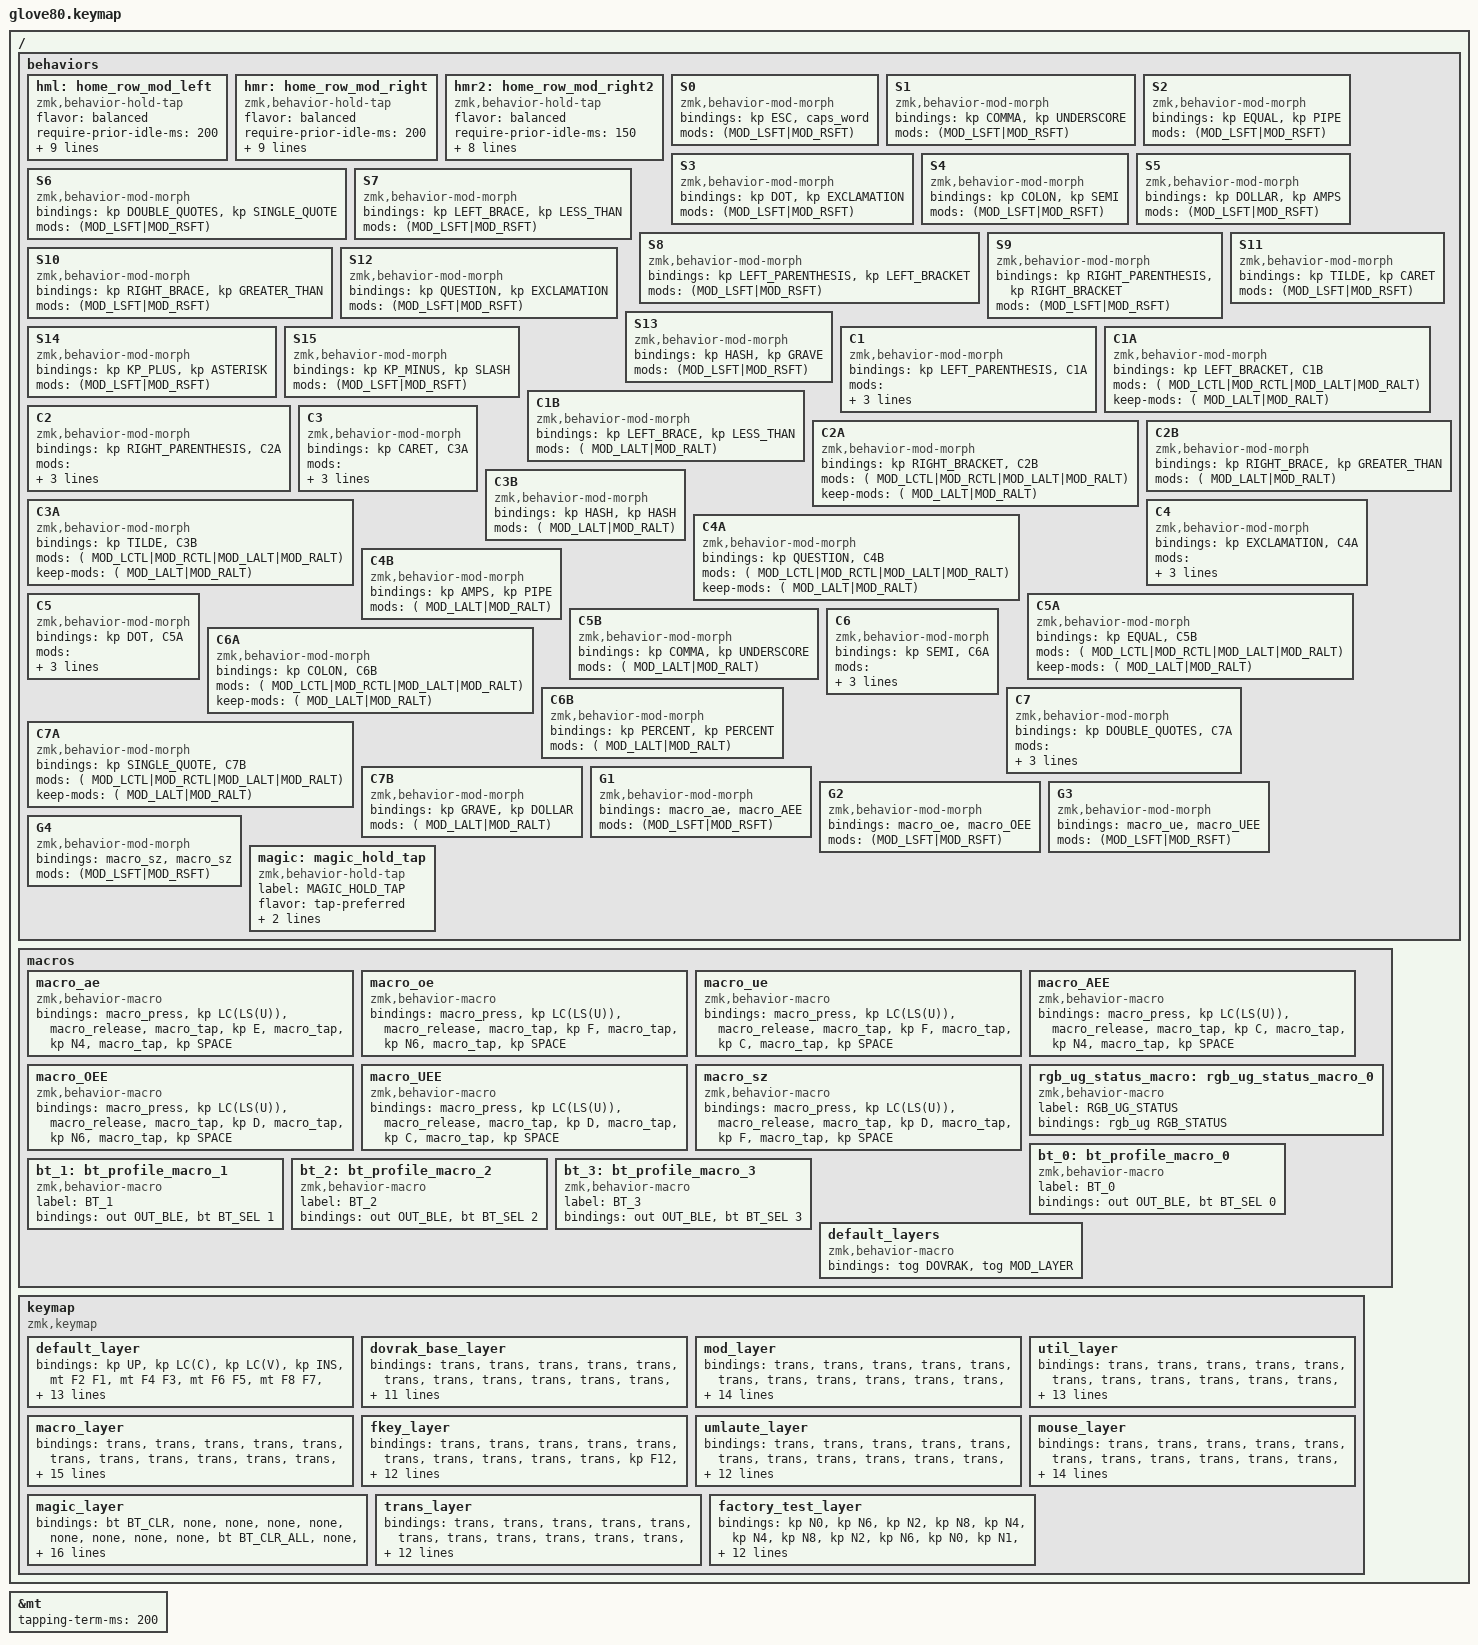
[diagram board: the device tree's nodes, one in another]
/*
 * Copyright (c) 2020 The ZMK Contributors
 *
 * SPDX-License-Identifier: MIT
 */

#include <behaviors.dtsi>
#include <dt-bindings/zmk/keys.h>
#include <dt-bindings/zmk/bt.h>
#include <dt-bindings/zmk/ext_power.h>
#include <dt-bindings/zmk/outputs.h>
#include <dt-bindings/zmk/rgb.h>
#include <dt-bindings/zmk/pointing.h>

#define HYPER LC(LA(LSHFT))

#define CUT   &kp LC(X)
#define COPY  &kp LC(C)
#define PASTE &kp LC(V)
#define PASTE_INS &kp LS(INS)

#define D16 &kp KP_SLASH                          // / when tapped
#define D17 &kp BACKSLASH                         // \ when tapped

// layers
#define DEFAULT                0
#define DOVRAK                 1
#define MOD_LAYER              2
#define UTIL                   3
#define MACRO_LAYER            4
#define FKEYS                  5
#define UMLAUTE                6
#define MOUSE                  7
#define MAGIC                  8

&mt {
//    flavor = "tap-preferred";
    tapping-term-ms = <200>;
};
//        #################################################  CUSTOM KEYS ################################################# //
//        ~~~~~~~~~~~~~~~~~~~~~~~~~~~~~~~~~~~~~~~~~~~~~~~~~  CUSTOM KEYS ~~~~~~~~~~~~~~~~~~~~~~~~~~~~~~~~~~~~~~~~~~~~~~~~~ //

// 0
// 1
// 2
// 3
// 4
// 5
// 6
// 7
// 8
// 9

// bindings = <
// &0     &1     &2     &3     &4                                                             &5     &6     &7     &8     &9
// &10    &11    &12    &13    &14    &15                                              &16    &17    &18    &19    &20    &21
// &22    &23    &24    &25    &26    &27                                              &28    &29    &30    &31    &32    &33
// &34    &35    &36    &37    &38    &39                                              &40    &41    &42    &43    &44    &45
// &46    &47    &48    &49    &50    &51    &52    &53    &54    &55    &56    &57    &58    &59    &60    &61    &62    &63
// &64    &65    &66    &67    &68           &69    &70    &71    &72    &73    &74           &75    &76    &77    &78    &79
// >;



/ {
    behaviors {
//        #################################################  HOMEROW MODS #################################################  //
        hml: home_row_mod_left {
            compatible = "zmk,behavior-hold-tap";
            #binding-cells = <2>;
            flavor = "balanced";
            require-prior-idle-ms = <200>;
            tapping-term-ms = <250>;
            quick-tap-ms = <180>;
            bindings = <&kp>, <&kp>;
            hold-trigger-key-positions = <5>,<6>,<7>,<8>,<9>,<16>,<17>,<18>,<19>,<20>,<21>,<28>,<29>,<30>,<31>,<32>,<33>,<40>,<41>,<42>,<43>,<44>,<45>,<59>,<60>,<61>,<62>,<63>,<75>,<76>,<77>,<78>,<79>, // List of keys on the right side of the keyboard
            <52>,<53>,<54>,<55>,<56>,<57>,<69>,<70>,<71>,<72>,<73>,<74>; //thumbs
            hold-trigger-on-release;
        };
        hmr: home_row_mod_right {
            compatible = "zmk,behavior-hold-tap";
            #binding-cells = <2>;
            flavor = "balanced";
            require-prior-idle-ms = <200>;
            tapping-term-ms = <250>;
            quick-tap-ms = <180>;
            bindings = <&kp>, <&kp>;
            hold-trigger-key-positions = <0>,<1>,<2>,<3>,<4>,<10>,<11>,<12>,<13>,<14>,<15>,<22>,<23>,<24>,<25>,<26>,<27>,<34>,<35>,<36>,<37>,<38>,<39>,<46>,<47>,<48>,<49>,<50>,<51>,<64>,<65>,<66>,<67>,<68>,// List of keys on the left side of the keyboard
            <52>,<53>,<54>,<55>,<56>,<57>,<69>,<70>,<71>,<72>,<73>,<74>; //thumbs
            hold-trigger-on-release;
        };

       hmr2: home_row_mod_right2 {
           compatible = "zmk,behavior-hold-tap";
           #binding-cells = <2>;
           flavor = "balanced";
           require-prior-idle-ms = <150>;
           tapping-term-ms = <180>;
           quick-tap-ms = <125>;
           bindings = <&mo>, <&kp>;
           hold-trigger-key-positions = <0>,<1>,<2>,<3>,<4>,<10>,<11>,<12>,<13>,<14>,<15>,<22>,<23>,<24>,<25>,<26>,<27>,<34>,<35>,<36>,<37>,<38>,<39>,<46>,<47>,<48>,<49>,<50>,<51>,<64>,<65>,<66>,<67>,<68>;// List of keys on the left side of the keyboard
           hold-trigger-on-release;
       };
//        ~~~~~~~~~~~~~~~~~~~~~~~~~~~~~~~~~~~~~~~~~~~~~~~~  HOMEROW MODS ~~~~~~~~~~~~~~~~~~~~~~~~~~~~~~~~~~~~~~~~~~~~~~~~  //
//        #################################################  CUSTOM KEYS ################################################# //
        S0: S0 {
                    compatible = "zmk,behavior-mod-morph";
                    #binding-cells = <0>;
                    bindings = <&kp ESC>, <&caps_word>;
                    mods = <(MOD_LSFT|MOD_RSFT)>;
        };

        S1: S1   { compatible = "zmk,behavior-mod-morph"; #binding-cells = <0>; bindings = <&kp COMMA>             , <&kp UNDERSCORE>      ; mods = <(MOD_LSFT|MOD_RSFT)>; };
        S2: S2   { compatible = "zmk,behavior-mod-morph"; #binding-cells = <0>; bindings = <&kp EQUAL>             , <&kp PIPE>            ; mods = <(MOD_LSFT|MOD_RSFT)>; };
        S3: S3   { compatible = "zmk,behavior-mod-morph"; #binding-cells = <0>; bindings = <&kp DOT>               , <&kp EXCLAMATION>     ; mods = <(MOD_LSFT|MOD_RSFT)>; };
        S4: S4   { compatible = "zmk,behavior-mod-morph"; #binding-cells = <0>; bindings = <&kp COLON>             , <&kp SEMI>            ; mods = <(MOD_LSFT|MOD_RSFT)>; };
        S5: S5   { compatible = "zmk,behavior-mod-morph"; #binding-cells = <0>; bindings = <&kp DOLLAR>            , <&kp AMPS>            ; mods = <(MOD_LSFT|MOD_RSFT)>; };
        S6: S6   { compatible = "zmk,behavior-mod-morph"; #binding-cells = <0>; bindings = <&kp DOUBLE_QUOTES>     , <&kp SINGLE_QUOTE>    ; mods = <(MOD_LSFT|MOD_RSFT)>; };
        S7: S7   { compatible = "zmk,behavior-mod-morph"; #binding-cells = <0>; bindings = <&kp LEFT_BRACE>        , <&kp LESS_THAN>       ; mods = <(MOD_LSFT|MOD_RSFT)>; };
        S8: S8   { compatible = "zmk,behavior-mod-morph"; #binding-cells = <0>; bindings = <&kp LEFT_PARENTHESIS>  , <&kp LEFT_BRACKET>    ; mods = <(MOD_LSFT|MOD_RSFT)>; };
        S9: S9   { compatible = "zmk,behavior-mod-morph"; #binding-cells = <0>; bindings = <&kp RIGHT_PARENTHESIS> , <&kp RIGHT_BRACKET>   ; mods = <(MOD_LSFT|MOD_RSFT)>; };
        S10: S10 { compatible = "zmk,behavior-mod-morph"; #binding-cells = <0>; bindings = <&kp RIGHT_BRACE>       , <&kp GREATER_THAN>    ; mods = <(MOD_LSFT|MOD_RSFT)>; };
        S11: S11 { compatible = "zmk,behavior-mod-morph"; #binding-cells = <0>; bindings = <&kp TILDE>             , <&kp CARET>           ; mods = <(MOD_LSFT|MOD_RSFT)>; };
        S12: S12 { compatible = "zmk,behavior-mod-morph"; #binding-cells = <0>; bindings = <&kp QUESTION>          , <&kp EXCLAMATION>     ; mods = <(MOD_LSFT|MOD_RSFT)>; };
        S13: S13 { compatible = "zmk,behavior-mod-morph"; #binding-cells = <0>; bindings = <&kp HASH>              , <&kp GRAVE>           ; mods = <(MOD_LSFT|MOD_RSFT)>; };
        S14: S14 { compatible = "zmk,behavior-mod-morph"; #binding-cells = <0>; bindings = <&kp KP_PLUS>           , <&kp ASTERISK>        ; mods = <(MOD_LSFT|MOD_RSFT)>; };
        S15: S15 { compatible = "zmk,behavior-mod-morph"; #binding-cells = <0>; bindings = <&kp KP_MINUS>          , <&kp SLASH>           ; mods = <(MOD_LSFT|MOD_RSFT)>; };

        // S7 & S8 ([{<
        C1:  C1    { compatible = "zmk,behavior-mod-morph"; #binding-cells = <0>; bindings = <&kp LEFT_PARENTHESIS>   , <&C1A>              ; mods = <(MOD_LSFT|MOD_RSFT|MOD_LCTL|MOD_RCTL|MOD_LALT|MOD_RALT)>; keep-mods = <(MOD_LCTL|MOD_RCTL|MOD_LALT|MOD_RALT)>; };
        C1A: C1A   { compatible = "zmk,behavior-mod-morph"; #binding-cells = <0>; bindings = <&kp LEFT_BRACKET>       , <&C1B>              ; mods = <(                  MOD_LCTL|MOD_RCTL|MOD_LALT|MOD_RALT)>; keep-mods = <(                  MOD_LALT|MOD_RALT)>; };
        C1B: C1B   { compatible = "zmk,behavior-mod-morph"; #binding-cells = <0>; bindings = <&kp LEFT_BRACE>         , <&kp LESS_THAN>     ; mods = <(                                    MOD_LALT|MOD_RALT)>;                                                      };
        // S9 & S10 )]}>
        C2:  C2    { compatible = "zmk,behavior-mod-morph"; #binding-cells = <0>; bindings = <&kp RIGHT_PARENTHESIS>  , <&C2A>             ; mods = <(MOD_LSFT|MOD_RSFT|MOD_LCTL|MOD_RCTL|MOD_LALT|MOD_RALT)>; keep-mods = <(MOD_LCTL|MOD_RCTL|MOD_LALT|MOD_RALT)>; };
        C2A: C2A   { compatible = "zmk,behavior-mod-morph"; #binding-cells = <0>; bindings = <&kp RIGHT_BRACKET>      , <&C2B>             ; mods = <(                  MOD_LCTL|MOD_RCTL|MOD_LALT|MOD_RALT)>; keep-mods = <(                  MOD_LALT|MOD_RALT)>; };
        C2B: C2B   { compatible = "zmk,behavior-mod-morph"; #binding-cells = <0>; bindings = <&kp RIGHT_BRACE>        , <&kp GREATER_THAN> ; mods = <(                                    MOD_LALT|MOD_RALT)>;                                                      };

        // ^~#
        C3:  C3    { compatible = "zmk,behavior-mod-morph"; #binding-cells = <0>; bindings = <&kp CARET>              , <&C3A>             ; mods = <(MOD_LSFT|MOD_RSFT|MOD_LCTL|MOD_RCTL|MOD_LALT|MOD_RALT)>; keep-mods = <(MOD_LCTL|MOD_RCTL|MOD_LALT|MOD_RALT)>; };
        C3A: C3A   { compatible = "zmk,behavior-mod-morph"; #binding-cells = <0>; bindings = <&kp TILDE>              , <&C3B>             ; mods = <(                  MOD_LCTL|MOD_RCTL|MOD_LALT|MOD_RALT)>; keep-mods = <(                  MOD_LALT|MOD_RALT)>; };
        C3B: C3B   { compatible = "zmk,behavior-mod-morph"; #binding-cells = <0>; bindings = <&kp HASH>               , <&kp HASH>         ; mods = <(                                    MOD_LALT|MOD_RALT)>;                                                      };

        // !?&|
        C4:  C4    { compatible = "zmk,behavior-mod-morph"; #binding-cells = <0>; bindings = <&kp EXCLAMATION>        , <&C4A>             ; mods = <(MOD_LSFT|MOD_RSFT|MOD_LCTL|MOD_RCTL|MOD_LALT|MOD_RALT)>; keep-mods = <(MOD_LCTL|MOD_RCTL|MOD_LALT|MOD_RALT)>; };
        C4A: C4A   { compatible = "zmk,behavior-mod-morph"; #binding-cells = <0>; bindings = <&kp QUESTION>           , <&C4B>             ; mods = <(                  MOD_LCTL|MOD_RCTL|MOD_LALT|MOD_RALT)>; keep-mods = <(                  MOD_LALT|MOD_RALT)>; };
        C4B: C4B   { compatible = "zmk,behavior-mod-morph"; #binding-cells = <0>; bindings = <&kp AMPS>               , <&kp PIPE>         ; mods = <(                                    MOD_LALT|MOD_RALT)>;                                                      };

        // .=,_
        C5:  C5    { compatible = "zmk,behavior-mod-morph"; #binding-cells = <0>; bindings = <&kp DOT>                , <&C5A>             ; mods = <(MOD_LSFT|MOD_RSFT|MOD_LCTL|MOD_RCTL|MOD_LALT|MOD_RALT)>; keep-mods = <(MOD_LCTL|MOD_RCTL|MOD_LALT|MOD_RALT)>; };
        C5A: C5A   { compatible = "zmk,behavior-mod-morph"; #binding-cells = <0>; bindings = <&kp EQUAL>              , <&C5B>             ; mods = <(                  MOD_LCTL|MOD_RCTL|MOD_LALT|MOD_RALT)>; keep-mods = <(                  MOD_LALT|MOD_RALT)>; };
        C5B: C5B   { compatible = "zmk,behavior-mod-morph"; #binding-cells = <0>; bindings = <&kp COMMA>              , <&kp UNDERSCORE>   ; mods = <(                                    MOD_LALT|MOD_RALT)>;                                                      };

        // :;%%
        C6:  C6    { compatible = "zmk,behavior-mod-morph"; #binding-cells = <0>; bindings = <&kp SEMI>               , <&C6A>             ; mods = <(MOD_LSFT|MOD_RSFT|MOD_LCTL|MOD_RCTL|MOD_LALT|MOD_RALT)>; keep-mods = <(MOD_LCTL|MOD_RCTL|MOD_LALT|MOD_RALT)>; };
        C6A: C6A   { compatible = "zmk,behavior-mod-morph"; #binding-cells = <0>; bindings = <&kp COLON>              , <&C6B>             ; mods = <(                  MOD_LCTL|MOD_RCTL|MOD_LALT|MOD_RALT)>; keep-mods = <(                  MOD_LALT|MOD_RALT)>; };
        C6B: C6B   { compatible = "zmk,behavior-mod-morph"; #binding-cells = <0>; bindings = <&kp PERCENT>            , <&kp PERCENT>      ; mods = <(                                    MOD_LALT|MOD_RALT)>;                                                      };

        // "'`
        C7:  C7    { compatible = "zmk,behavior-mod-morph"; #binding-cells = <0>; bindings = <&kp DOUBLE_QUOTES>      , <&C7A>             ; mods = <(MOD_LSFT|MOD_RSFT|MOD_LCTL|MOD_RCTL|MOD_LALT|MOD_RALT)>; keep-mods = <(MOD_LCTL|MOD_RCTL|MOD_LALT|MOD_RALT)>; };
        C7A: C7A   { compatible = "zmk,behavior-mod-morph"; #binding-cells = <0>; bindings = <&kp SINGLE_QUOTE>       , <&C7B>             ; mods = <(                  MOD_LCTL|MOD_RCTL|MOD_LALT|MOD_RALT)>; keep-mods = <(                  MOD_LALT|MOD_RALT)>; };
        C7B: C7B   { compatible = "zmk,behavior-mod-morph"; #binding-cells = <0>; bindings = <&kp GRAVE>              , <&kp DOLLAR>       ; mods = <(                                    MOD_LALT|MOD_RALT)>;                                                      };

        // a A
        G1:  G1    { compatible = "zmk,behavior-mod-morph"; #binding-cells = <0>; bindings = <&macro_ae>   , <&macro_AEE>   ; mods = <(MOD_LSFT|MOD_RSFT)>; };
        G2:  G2    { compatible = "zmk,behavior-mod-morph"; #binding-cells = <0>; bindings = <&macro_oe>   , <&macro_OEE>   ; mods = <(MOD_LSFT|MOD_RSFT)>; };
        G3:  G3    { compatible = "zmk,behavior-mod-morph"; #binding-cells = <0>; bindings = <&macro_ue>   , <&macro_UEE>   ; mods = <(MOD_LSFT|MOD_RSFT)>; };
        G4:  G4    { compatible = "zmk,behavior-mod-morph"; #binding-cells = <0>; bindings = <&macro_sz>   , <&macro_sz>    ; mods = <(MOD_LSFT|MOD_RSFT)>; };
//        ~~~~~~~~~~~~~~~~~~~~~~~~~~~~~~~~~~~~~~~~~~~~~~~~~  CUSTOM KEYS ~~~~~~~~~~~~~~~~~~~~~~~~~~~~~~~~~~~~~~~~~~~~~~~~~ //

        magic: magic_hold_tap {
            compatible = "zmk,behavior-hold-tap";
            label = "MAGIC_HOLD_TAP";
            #binding-cells = <2>;
            flavor = "tap-preferred";
            tapping-term-ms = <200>;
            bindings = <&mo>, <&rgb_ug_status_macro>;
        };
    };

    macros {
//        #################################################  ASCII KEYS ################################################# //
        // ä (U+00E4)
        macro_ae: macro_ae {
            compatible = "zmk,behavior-macro";
            #binding-cells = <0>;
            bindings
              = <&macro_press &kp LC(LS(U))>
              , <&macro_release>
              , <&macro_tap &kp E>
              , <&macro_tap &kp N4>
              , <&macro_tap &kp SPACE>
              ;
        };

        // ö (U+00F6)
        macro_oe: macro_oe {
            compatible = "zmk,behavior-macro";
            #binding-cells = <0>;
            bindings
              = <&macro_press &kp LC(LS(U))>
              , <&macro_release>
              , <&macro_tap &kp F>
              , <&macro_tap &kp N6>
              , <&macro_tap &kp SPACE>
              ;
        };

        // ü (U+00FC)
        macro_ue: macro_ue {
            compatible = "zmk,behavior-macro";
            #binding-cells = <0>;
            bindings
              = <&macro_press &kp LC(LS(U))>
              , <&macro_release>
              , <&macro_tap &kp F>
              , <&macro_tap &kp C>
              , <&macro_tap &kp SPACE>
              ;
        };

        // Ä (U+00C4)
        macro_AEE: macro_AEE {
            compatible = "zmk,behavior-macro";
            #binding-cells = <0>;
            bindings
              = <&macro_press &kp LC(LS(U))>
              , <&macro_release>
              , <&macro_tap &kp C>
              , <&macro_tap &kp N4>
              , <&macro_tap &kp SPACE>
              ;
        };

        // Ö (U+00D6)
        macro_OEE: macro_OEE {
            compatible = "zmk,behavior-macro";
            #binding-cells = <0>;
            bindings
              = <&macro_press &kp LC(LS(U))>
              , <&macro_release>
              , <&macro_tap &kp D>
              , <&macro_tap &kp N6>
              , <&macro_tap &kp SPACE>
              ;
        };

        // Ü (U+00DC)
        macro_UEE: macro_UEE {
            compatible = "zmk,behavior-macro";
            #binding-cells = <0>;
            bindings
              = <&macro_press &kp LC(LS(U))>
              , <&macro_release>
              , <&macro_tap &kp D>
              , <&macro_tap &kp C>
              , <&macro_tap &kp SPACE>
              ;
        };

        // ß (U+00DF)
        macro_sz: macro_sz {
            compatible = "zmk,behavior-macro";
            #binding-cells = <0>;
            bindings
              = <&macro_press &kp LC(LS(U))>
              , <&macro_release>
              , <&macro_tap &kp D>
              , <&macro_tap &kp F>
              , <&macro_tap &kp SPACE>
              ;
        };
//        ~~~~~~~~~~~~~~~~~~~~~~~~~~~~~~~~~~~~~~~~~~~~~~~~~  ASCII KEYS ~~~~~~~~~~~~~~~~~~~~~~~~~~~~~~~~~~~~~~~~~~~~~~~~~ //
        rgb_ug_status_macro: rgb_ug_status_macro_0 {
            label = "RGB_UG_STATUS";
            compatible = "zmk,behavior-macro";
            #binding-cells = <0>;
            bindings
                = <&rgb_ug RGB_STATUS>;
        };

        bt_0: bt_profile_macro_0 {
            label = "BT_0";
            compatible = "zmk,behavior-macro";
            #binding-cells = <0>;
            bindings
                = <&out OUT_BLE>,
                  <&bt BT_SEL 0>;
        };

        bt_1: bt_profile_macro_1 {
            label = "BT_1";
            compatible = "zmk,behavior-macro";
            #binding-cells = <0>;
            bindings
                = <&out OUT_BLE>,
                  <&bt BT_SEL 1>;
        };

        bt_2: bt_profile_macro_2 {
            label = "BT_2";
            compatible = "zmk,behavior-macro";
            #binding-cells = <0>;
            bindings
                = <&out OUT_BLE>,
                  <&bt BT_SEL 2>;
        };

        bt_3: bt_profile_macro_3 {
            label = "BT_3";
            compatible = "zmk,behavior-macro";
            #binding-cells = <0>;
            bindings
                = <&out OUT_BLE>,
                  <&bt BT_SEL 3>;
        };

         default_layers: default_layers {
                      compatible = "zmk,behavior-macro";
                      #binding-cells = <0>;
                      bindings
                        = <&tog DOVRAK>
                        , <&tog MOD_LAYER>
                        ;
                  };
    };

    keymap {
        compatible = "zmk,keymap";

        default_layer {
            // ----------------------------------------------------------------------------------------------------------------------------------------------
            // |            |     |     |      | F1 F2 |                                                         | F3 F4 | F5 F6 | F7 F8 | F9 F10 | F11 F12 |
            // |            |  1  |  2  |  3   | 4     | 5 |                                                 | 6 | 7     | 8     | 9     | 0      |         |
            // |  ESC       |     |     |      |       |   |                                                 |   |       |       |       |        |         |
            // |  TAB CAPS  |     |     |      |       |   |                                                 |   |       |       |       |        |         |
            // |            |     |     |      |       |   | LSHFT | LCTRL | LOWER | | LGUI  | RCTRL | RSHFT |   |       |       |       |        | PGUP    |
            // | MAGIC      | HOME| END | LEFT | RIGHT |   | BSPC  | DEL   | LALT  | | RALT  | RET   | SPACE |   | UP    | DOWN  |       |        | PGDN    |

            bindings = <
            &kp UP         &kp LC(C)       &kp LC(V)    &kp INS     &mt F2 F1                                                                                         &mt F4 F3  &mt F6 F5      &mt F8 F7      &mt F10 F9     &mt F12 F11
            &kp DOWN       &kp N1          &kp N2       &kp N3      &kp N4      &kp N5                                                                        &kp N6  &kp N7     &kp N8         &kp N9         &kp N0         &none
            &kp ESC        &none           &none        &none       &none       &none                                                                         &none   &none      &none          &none          &none          &none
            &kp TAB        &none           &none        &none       &none       &none                                                                         &none   &none      &none          &none          &none          &none
            &none          &none           &none        &none       &none       &none   &kp LSHFT   &kp LCTRL   &kp LGUI   &kp LGUI   &kp RSHFT   &kp DEL     &none   &none      &none          &none          &none          &kp PG_UP
            &magic MAGIC 0 &kp HOME        &kp END      &kp LEFT    &kp RIGHT           &kp SPACE   &kp RET     &kp LALT   &mo MOUSE  &tog MOUSE  &kp BSPC            &kp UP     &kp DOWN       &none          &none          &kp PG_DN
            >;
        };
//        &kp LSHFT   &kp LCTRL   &kp LGUI   &kp LGUI  &kp RCTRL &kp RSHFT
//        &kp BSPC    &kp DEL     &kp LALT   &kp LALT  &kp RET   &kp SPACE

        dovrak_base_layer {

           bindings = <
           &trans      &trans      &trans      &trans      &trans                                                                             &trans      &trans      &trans      &trans      &trans
           &trans      &trans      &trans      &trans      &trans             &trans                                                  &trans  &trans      &trans      &trans      &trans      &trans
           &trans      &C3         &C4         &C5         &C6                &C7                                                     &kp G   &kp K       &kp R       &kp F       &kp J       &mo FKEYS
           &trans      &kp A       &kp O       &kp E       &kp U              &kp I                                                   &kp D   &kp H       &kp T       &kp N       &kp B       &kp X
           &kp V       &kp Z       &kp P       &kp Y       &mo MACRO_LAYER    &kp M   &trans  &trans  &trans  &trans  &trans  &trans  &kp W   &kp S       &kp C       &kp L       &kp Q       &trans
           &trans      &trans      &trans      &trans      &trans                     &trans  &trans  &trans  &trans  &trans  &trans          &trans      &trans      &S14        &S15        &trans
          >;
        };

        mod_layer {

           bindings = <
           &trans  &trans      &trans        &trans         &trans                                                                            &trans         &trans         &trans       &trans           &trans
           &trans  &trans      &trans        &trans         &trans         &trans                                                     &trans  &trans         &trans         &trans       &trans           &trans
           &trans  &trans      &trans        &trans         &trans         &trans                                                     &trans  &trans         &trans         &trans       &trans           &trans
           &trans  &hml LGUI A &hml LALT O   &hml LCTRL E   &hml LSHFT U   &hml ESC I                                                 &trans  &hmr LSHFT H   &hmr LCTRL T   &hmr LALT N  &hmr LGUI B      &trans
           &trans  &trans      &trans        &trans         &trans         &trans    &trans  &trans  &trans  &trans  &trans  &trans   &trans  &trans         &hmr HYPER C   &trans       &hmr2 UMLAUTE Q  &trans
           &trans  &trans      &trans        &trans         &trans                   &trans  &trans  &trans  &trans  &trans  &trans           &trans         &trans         &trans       &trans           &trans
           >;
        };

        util_layer {
           bindings = <
           &trans  &trans  &trans    &trans    &trans                                                                                       &trans  &trans  &trans     &trans           &trans
           &trans  &trans  &trans    &trans    &trans            &trans                                                          &trans     &trans  &trans  &trans     &trans           &trans
           &trans  &none   &kp HOME  &kp UP    &kp END           &kp PG_UP                                                       &kp COLON  &kp N7  &kp N8  &kp N9     &kp KP_PLUS      &none
           &trans  &none   &kp LEFT  &kp DOWN  &kp RIGHT         &kp PG_DN                                                       &kp DOT    &kp N4  &kp N5  &kp N6     &kp KP_MINUS     &none
           &trans  &none   &none     &none     &mo MACRO_LAYER   &kp RALT  &trans    &trans  &trans  &trans  &trans  &trans      &kp N0     &kp N1  &kp N2  &kp N3     &kp KP_MULTIPLY  &none
           &trans  &none   &none     &none     &none                       &trans    &trans  &trans  &trans  &trans  &trans                 &none   &none   &kp EQUAL  &kp KP_DIVIDE    &none
           >;
        };

        macro_layer {
           // ----------------------------------------------------------------------------------------------------
           // |    |        |           |        |   |                                         |        |           |      |     |     |
           // |    |        |           |        |   |   |                           |         |        |           |      |     |     |
           // |    | actions| dupli     | save   |   |   |                           | crtl F4 |        |  /        |  \   |     |     |
           // |    | l-edit | undo      | copy   |   |   |                           |         |        | run       |format| ß   |     |
           // |    | crtl x |  J        |  K     |   |ins|   |   |   |   |   |   |   | B       | X      | V         | Q    | Z   |     |
           // |    | ä Ä    | ö Ö       | ü Ü    |   |   |   |   |   |   |   |   |   |         |        |           |      |     |     |
             bindings = <
           &trans      &trans           &trans            &trans            &trans                                                                                         &trans           &trans           &trans          &trans         &trans
           &trans      &trans           &trans            &trans            &trans   &trans                                                             &trans             &trans           &trans           &trans          &trans         &trans
           &trans      &kp LC(LS(BSPC)) &kp LC(D)         &kp LC(S)         &trans   &kp LG(LS(S))                                                      &kp LC(F4)         &none            D16              D17             &none          &trans
           &kp CAPS    &kp LC(X)        &kp LC(Z)         &kp LC(C)         &trans   &kp LS(INS)                                                        &kp LC(LS(BSPC))   &kp LC(LS(F9))   &kp LC(LS(F10))  &kp LC(F5)      &none          &trans
           &caps_word  &kp LC(W)        &kp LC(F)         &kp LC(R)         &none    &kp LC(V)  &kp LC(F) &kp LC(R) &kp LC(X)  &trans  &trans  &trans   &none              &none            &C1              &C2             &none          &trans
           &trans      &trans           &kp UP            &kp DOWN          &none               &kp BSPC  &kp DEL   &trans     &trans  &trans  &kp TAB                     &trans           &trans           &trans          &trans         &trans
          >;
        };

        //F Key layer
        fkey_layer {
           // ------------------------------------------------------------------------------
           // |    |   |   |   |   |                                   |   |   |   |   |   |
           // |    |   |   |   |   |   |                           |   |   |   |   |   |   |
           // |    |   |   |   |   |   |                           |   |   |   |   |   |   |
           // |    |   |   |   |   |   |                           |   |   |   |   |   |   |
           // |    |   |   |   |   |   |   |   |   |   |   |   |   |   |   |   |   |   |   |
           // |    |   |   |   |   |   |   |   |   |   |   |   |   |   |   |   |   |   |   |
           bindings = <
           &trans  &trans  &trans  &trans  &trans                                                                   &trans  &trans  &trans  &trans   &trans
           &kp F12 &kp F1  &kp F2  &kp F3  &kp F4   &kp F5                                                  &kp F6  &kp F7  &kp F8  &kp F9  &kp F10  &kp F11
           &trans  &trans  &trans  &trans  &trans   &trans                                                  &trans  &trans  &trans  &trans  &trans   &trans
           &trans  &trans  &trans  &trans  &trans   &trans                                                  &trans  &trans  &trans  &trans  &trans   &trans
           &trans  &trans  &trans  &trans  &trans   &trans  &trans  &trans  &trans  &trans  &trans  &trans  &trans  &trans  &trans  &trans  &trans   &trans
           &trans  &trans  &trans  &trans  &trans           &trans  &trans  &trans  &trans  &trans  &trans          &trans  &trans  &trans  &trans   &trans
           >;
        };

        umlaute_layer {
           // ------------------------------------------------------------------------------
           // |    |   |   |   |   |                                   |   |   |   |   |   |
           // |    |   |   |   |   |   |                           |   |   |   |   |   |   |
           // |    |   |   |   |   |   |                           |   |   |   |   |   |   |
           // |    |   |   |   |   |   |                           |   |   |   |   |   |   |
           // |    |   |   |   |   |   |   |   |   |   |   |   |   |   |   |   |   |   |   |
           // |    |   |   |   |   |   |   |   |   |   |   |   |   |   |   |   |   |   |   |
           bindings = <
           &trans  &trans  &trans  &trans  &trans                                                                  &trans  &trans  &trans  &trans  &trans
           &trans  &trans  &trans  &trans  &trans  &trans                                                  &trans  &trans  &trans  &trans  &trans  &trans
           &trans  &trans  &trans  &trans  &trans  &trans                                                  &trans  &trans  &trans  &trans  &trans  &trans
           &trans  &G1     &G2     &trans  &G3     &G4                                                     &trans  &trans  &trans  &trans  &trans  &trans
           &trans  &trans  &trans  &trans  &trans  &trans  &trans  &trans  &trans  &trans  &trans  &trans  &trans  &trans  &trans  &trans  &trans  &trans
           &trans  &trans  &trans  &trans  &trans          &trans  &trans  &trans  &trans  &trans  &trans          &trans  &trans  &trans  &trans  &trans
           >;
        };

        // under construction
        // ref https://sunaku.github.io/moergo-glove80-keyboard.html#layers
        // ref https://zmk.dev/docs/keymaps/behaviors/mouse-emulation
        mouse_layer {
           // ------------------------------------------------------------------------------
           // |    |   |   |   |   |                                   |   |   |   |   |   |
           // |    |   |   |   |   |   |                           |   |   |   |   |   |   |
           // |    |   |   |   |   |   |                           |   |   |   |   |   |   |
           // |    |   |   |   |   |   |                           |   |   |   |   |   |   |
           // |    |   |   |   |   |   |   |   |   |   |   |   |   |   |   |   |   |   |   |
           // |    |   |   |   |   |   |   |   |   |   |   |   |   |   |   |   |   |   |   |
           bindings = <
           &trans  &trans     &trans         &trans          &trans                                                                             &trans  &trans  &trans  &trans  &trans
           &trans  &trans     &trans         &trans          &trans          &trans                                                     &trans  &trans  &trans  &trans  &trans  &trans
           &trans  &trans     &trans         &mmv MOVE_UP    &trans          CUT                                                        &trans  &trans  &trans  &trans  &trans  &trans
           &trans  &trans     &mmv MOVE_LEFT &mmv MOVE_DOWN  &mmv MOVE_RIGHT COPY                                                       &trans  &trans  &trans  &trans  &trans  &trans
           &trans  &trans     &msc SCRL_LEFT &msc SCRL_RIGHT &msc SCRL_UP    PASTE   &mkp MB3 &trans   &mkp MB4 &trans  &trans  &trans  &trans  &trans  &trans  &trans  &trans  &trans
           &trans  &trans     &trans         &trans          &msc SCRL_DOWN          &mkp MB1 &mkp MB2 &mkp MB5 &trans  &trans  &trans          &trans  &trans  &trans  &trans  &trans
           >;
        };

        magic_layer {
            bindings = <
            &bt BT_CLR  &none           &none           &none           &none                                                                                  &none           &none        &none      &none      &bt BT_CLR_ALL
            &none       &none           &none           &none           &none           &none                                                       &none      &none           &none        &none      &none      &none
            &none       &rgb_ug RGB_SPI &rgb_ug RGB_SAI &rgb_ug RGB_HUI &rgb_ug RGB_BRI &rgb_ug RGB_TOG                                             &kp C_MUTE &kp C_VOL_DN    &kp C_VOL_UP &kp C_NEXT &kp C_PREV &none
            &bootloader &rgb_ug RGB_SPD &rgb_ug RGB_SAD &rgb_ug RGB_HUD &rgb_ug RGB_BRD &rgb_ug RGB_EFF                                             &kp K_APP  &tog UTIL       &tog FKEYS   &none      &none      &bootloader
            &sys_reset  &none           &none           &none           &none           &none           &bt_2 &bt_3 &none        &none &none &none  &none      &default_layers &none        &none      &none      &sys_reset
            &none       &none           &none           &none           &none                           &bt_0 &bt_1 &out OUT_USB &none &none &none             &none           &none        &none      &none      &none
            >;
        };

        // Template for new layer
        trans_layer {
           // ------------------------------------------------------------------------------
           // |    |   |   |   |   |                                   |   |   |   |   |   |
           // |    |   |   |   |   |   |                           |   |   |   |   |   |   |
           // |    |   |   |   |   |   |                           |   |   |   |   |   |   |
           // |    |   |   |   |   |   |                           |   |   |   |   |   |   |
           // |    |   |   |   |   |   |   |   |   |   |   |   |   |   |   |   |   |   |   |
           // |    |   |   |   |   |   |   |   |   |   |   |   |   |   |   |   |   |   |   |
           bindings = <
           &trans  &trans  &trans  &trans  &trans                                                                  &trans  &trans  &trans  &trans  &trans
           &trans  &trans  &trans  &trans  &trans  &trans                                                  &trans  &trans  &trans  &trans  &trans  &trans
           &trans  &trans  &trans  &trans  &trans  &trans                                                  &trans  &trans  &trans  &trans  &trans  &trans
           &trans  &trans  &trans  &trans  &trans  &trans                                                  &trans  &trans  &trans  &trans  &trans  &trans
           &trans  &trans  &trans  &trans  &trans  &trans  &trans  &trans  &trans  &trans  &trans  &trans  &trans  &trans  &trans  &trans  &trans  &trans
           &trans  &trans  &trans  &trans  &trans          &trans  &trans  &trans  &trans  &trans  &trans          &trans  &trans  &trans  &trans  &trans
           >;
        };


        factory_test_layer {
            bindings = <
            &kp N0   &kp N6   &kp N2   &kp N8   &kp N4                                                                              &kp N4   &kp N8   &kp N2   &kp N6   &kp N0
            &kp N1   &kp N7   &kp N3   &kp N9   &kp N5   &kp N0                                                            &kp N0   &kp N5   &kp N9   &kp N3   &kp N7   &kp N1
            &kp N2   &kp N8   &kp N4   &kp N0   &kp N6   &kp N1                                                            &kp N1   &kp N6   &kp N0   &kp N4   &kp N8   &kp N2
            &kp N3   &kp N9   &kp N5   &kp N1   &kp N7   &kp N2                                                            &kp N2   &kp N7   &kp N1   &kp N5   &kp N9   &kp N3
            &kp N4   &kp N0   &kp N6   &kp N2   &kp N8   &kp N3   &kp N4   &kp N5   &kp N6      &kp N6   &kp N5   &kp N4   &kp N3   &kp N8   &kp N2   &kp N6   &kp N0   &kp N4
            &kp N5   &kp N1   &kp N7   &kp N3   &kp N9            &kp N7   &kp N8   &kp N9      &kp N9   &kp N8   &kp N7            &kp N9   &kp N3   &kp N7   &kp N1   &kp N5
            >;
        };
    };
};
